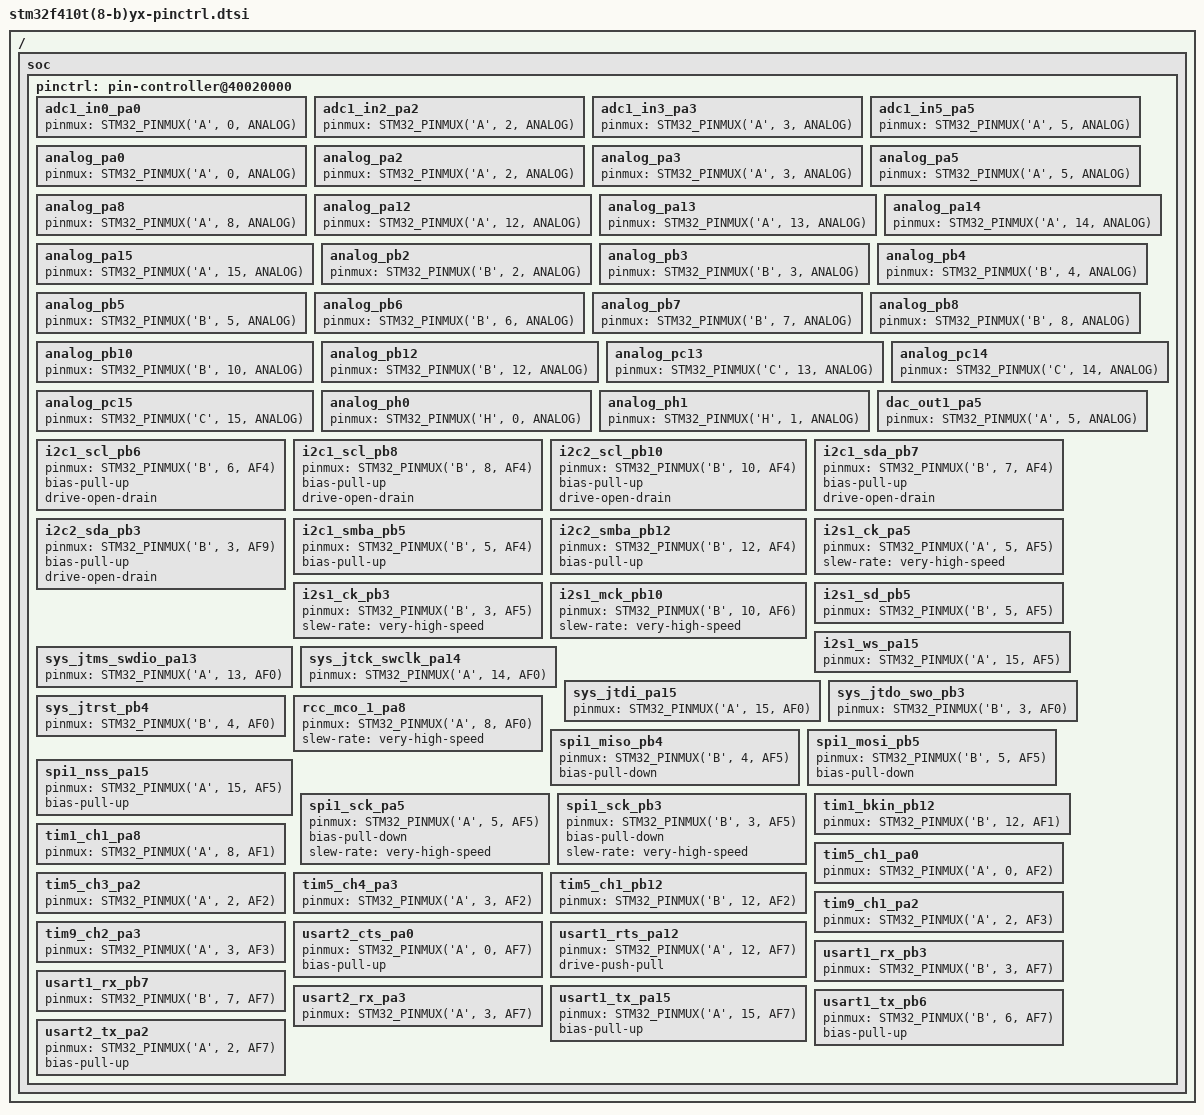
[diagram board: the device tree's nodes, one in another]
/*
 * NOTE: Autogenerated file using genpinctrl.py
 *
 * SPDX-License-Identifier: Apache-2.0
 */

#include <zephyr/dt-bindings/pinctrl/stm32-pinctrl.h>

/ {
	soc {
		pinctrl: pin-controller@40020000 {

			/* ADC_IN / ADC_INN / ADC_INP */

			/omit-if-no-ref/ adc1_in0_pa0: adc1_in0_pa0 {
				pinmux = <STM32_PINMUX('A', 0, ANALOG)>;
			};

			/omit-if-no-ref/ adc1_in2_pa2: adc1_in2_pa2 {
				pinmux = <STM32_PINMUX('A', 2, ANALOG)>;
			};

			/omit-if-no-ref/ adc1_in3_pa3: adc1_in3_pa3 {
				pinmux = <STM32_PINMUX('A', 3, ANALOG)>;
			};

			/omit-if-no-ref/ adc1_in5_pa5: adc1_in5_pa5 {
				pinmux = <STM32_PINMUX('A', 5, ANALOG)>;
			};

			/* Analog */

			/omit-if-no-ref/ analog_pa0: analog_pa0 {
				pinmux = <STM32_PINMUX('A', 0, ANALOG)>;
			};

			/omit-if-no-ref/ analog_pa2: analog_pa2 {
				pinmux = <STM32_PINMUX('A', 2, ANALOG)>;
			};

			/omit-if-no-ref/ analog_pa3: analog_pa3 {
				pinmux = <STM32_PINMUX('A', 3, ANALOG)>;
			};

			/omit-if-no-ref/ analog_pa5: analog_pa5 {
				pinmux = <STM32_PINMUX('A', 5, ANALOG)>;
			};

			/omit-if-no-ref/ analog_pa8: analog_pa8 {
				pinmux = <STM32_PINMUX('A', 8, ANALOG)>;
			};

			/omit-if-no-ref/ analog_pa12: analog_pa12 {
				pinmux = <STM32_PINMUX('A', 12, ANALOG)>;
			};

			/omit-if-no-ref/ analog_pa13: analog_pa13 {
				pinmux = <STM32_PINMUX('A', 13, ANALOG)>;
			};

			/omit-if-no-ref/ analog_pa14: analog_pa14 {
				pinmux = <STM32_PINMUX('A', 14, ANALOG)>;
			};

			/omit-if-no-ref/ analog_pa15: analog_pa15 {
				pinmux = <STM32_PINMUX('A', 15, ANALOG)>;
			};

			/omit-if-no-ref/ analog_pb2: analog_pb2 {
				pinmux = <STM32_PINMUX('B', 2, ANALOG)>;
			};

			/omit-if-no-ref/ analog_pb3: analog_pb3 {
				pinmux = <STM32_PINMUX('B', 3, ANALOG)>;
			};

			/omit-if-no-ref/ analog_pb4: analog_pb4 {
				pinmux = <STM32_PINMUX('B', 4, ANALOG)>;
			};

			/omit-if-no-ref/ analog_pb5: analog_pb5 {
				pinmux = <STM32_PINMUX('B', 5, ANALOG)>;
			};

			/omit-if-no-ref/ analog_pb6: analog_pb6 {
				pinmux = <STM32_PINMUX('B', 6, ANALOG)>;
			};

			/omit-if-no-ref/ analog_pb7: analog_pb7 {
				pinmux = <STM32_PINMUX('B', 7, ANALOG)>;
			};

			/omit-if-no-ref/ analog_pb8: analog_pb8 {
				pinmux = <STM32_PINMUX('B', 8, ANALOG)>;
			};

			/omit-if-no-ref/ analog_pb10: analog_pb10 {
				pinmux = <STM32_PINMUX('B', 10, ANALOG)>;
			};

			/omit-if-no-ref/ analog_pb12: analog_pb12 {
				pinmux = <STM32_PINMUX('B', 12, ANALOG)>;
			};

			/omit-if-no-ref/ analog_pc13: analog_pc13 {
				pinmux = <STM32_PINMUX('C', 13, ANALOG)>;
			};

			/omit-if-no-ref/ analog_pc14: analog_pc14 {
				pinmux = <STM32_PINMUX('C', 14, ANALOG)>;
			};

			/omit-if-no-ref/ analog_pc15: analog_pc15 {
				pinmux = <STM32_PINMUX('C', 15, ANALOG)>;
			};

			/omit-if-no-ref/ analog_ph0: analog_ph0 {
				pinmux = <STM32_PINMUX('H', 0, ANALOG)>;
			};

			/omit-if-no-ref/ analog_ph1: analog_ph1 {
				pinmux = <STM32_PINMUX('H', 1, ANALOG)>;
			};

			/* DAC_OUT */

			/omit-if-no-ref/ dac_out1_pa5: dac_out1_pa5 {
				pinmux = <STM32_PINMUX('A', 5, ANALOG)>;
			};

			/* I2C_SCL */

			/omit-if-no-ref/ i2c1_scl_pb6: i2c1_scl_pb6 {
				pinmux = <STM32_PINMUX('B', 6, AF4)>;
				bias-pull-up;
				drive-open-drain;
			};

			/omit-if-no-ref/ i2c1_scl_pb8: i2c1_scl_pb8 {
				pinmux = <STM32_PINMUX('B', 8, AF4)>;
				bias-pull-up;
				drive-open-drain;
			};

			/omit-if-no-ref/ i2c2_scl_pb10: i2c2_scl_pb10 {
				pinmux = <STM32_PINMUX('B', 10, AF4)>;
				bias-pull-up;
				drive-open-drain;
			};

			/* I2C_SDA */

			/omit-if-no-ref/ i2c1_sda_pb7: i2c1_sda_pb7 {
				pinmux = <STM32_PINMUX('B', 7, AF4)>;
				bias-pull-up;
				drive-open-drain;
			};

			/omit-if-no-ref/ i2c2_sda_pb3: i2c2_sda_pb3 {
				pinmux = <STM32_PINMUX('B', 3, AF9)>;
				bias-pull-up;
				drive-open-drain;
			};

			/* I2C_SMBA */

			/omit-if-no-ref/ i2c1_smba_pb5: i2c1_smba_pb5 {
				pinmux = <STM32_PINMUX('B', 5, AF4)>;
				bias-pull-up;
			};

			/omit-if-no-ref/ i2c2_smba_pb12: i2c2_smba_pb12 {
				pinmux = <STM32_PINMUX('B', 12, AF4)>;
				bias-pull-up;
			};

			/* I2S_CK */

			/omit-if-no-ref/ i2s1_ck_pa5: i2s1_ck_pa5 {
				pinmux = <STM32_PINMUX('A', 5, AF5)>;
				slew-rate = "very-high-speed";
			};

			/omit-if-no-ref/ i2s1_ck_pb3: i2s1_ck_pb3 {
				pinmux = <STM32_PINMUX('B', 3, AF5)>;
				slew-rate = "very-high-speed";
			};

			/* I2S_MCK */

			/omit-if-no-ref/ i2s1_mck_pb10: i2s1_mck_pb10 {
				pinmux = <STM32_PINMUX('B', 10, AF6)>;
				slew-rate = "very-high-speed";
			};

			/* I2S_SD */

			/omit-if-no-ref/ i2s1_sd_pb5: i2s1_sd_pb5 {
				pinmux = <STM32_PINMUX('B', 5, AF5)>;
			};

			/* I2S_WS */

			/omit-if-no-ref/ i2s1_ws_pa15: i2s1_ws_pa15 {
				pinmux = <STM32_PINMUX('A', 15, AF5)>;
			};

			/* JTAG PORT */

			/omit-if-no-ref/ sys_jtms_swdio_pa13: sys_jtms_swdio_pa13 {
				pinmux = <STM32_PINMUX('A', 13, AF0)>;
			};

			/omit-if-no-ref/ sys_jtck_swclk_pa14: sys_jtck_swclk_pa14 {
				pinmux = <STM32_PINMUX('A', 14, AF0)>;
			};

			/omit-if-no-ref/ sys_jtdi_pa15: sys_jtdi_pa15 {
				pinmux = <STM32_PINMUX('A', 15, AF0)>;
			};

			/omit-if-no-ref/ sys_jtdo_swo_pb3: sys_jtdo_swo_pb3 {
				pinmux = <STM32_PINMUX('B', 3, AF0)>;
			};

			/omit-if-no-ref/ sys_jtrst_pb4: sys_jtrst_pb4 {
				pinmux = <STM32_PINMUX('B', 4, AF0)>;
			};

			/* RCC_MCO */

			/omit-if-no-ref/ rcc_mco_1_pa8: rcc_mco_1_pa8 {
				pinmux = <STM32_PINMUX('A', 8, AF0)>;
				slew-rate = "very-high-speed";
			};

			/* SPI_MISO */

			/omit-if-no-ref/ spi1_miso_pb4: spi1_miso_pb4 {
				pinmux = <STM32_PINMUX('B', 4, AF5)>;
				bias-pull-down;
			};

			/* SPI_MOSI */

			/omit-if-no-ref/ spi1_mosi_pb5: spi1_mosi_pb5 {
				pinmux = <STM32_PINMUX('B', 5, AF5)>;
				bias-pull-down;
			};

			/* SPI_NSS */

			/omit-if-no-ref/ spi1_nss_pa15: spi1_nss_pa15 {
				pinmux = <STM32_PINMUX('A', 15, AF5)>;
				bias-pull-up;
			};

			/* SPI_SCK */

			/omit-if-no-ref/ spi1_sck_pa5: spi1_sck_pa5 {
				pinmux = <STM32_PINMUX('A', 5, AF5)>;
				bias-pull-down;
				slew-rate = "very-high-speed";
			};

			/omit-if-no-ref/ spi1_sck_pb3: spi1_sck_pb3 {
				pinmux = <STM32_PINMUX('B', 3, AF5)>;
				bias-pull-down;
				slew-rate = "very-high-speed";
			};

			/* TIM_BKIN */

			/omit-if-no-ref/ tim1_bkin_pb12: tim1_bkin_pb12 {
				pinmux = <STM32_PINMUX('B', 12, AF1)>;
			};

			/* TIM_CH / TIM_CHN */

			/omit-if-no-ref/ tim1_ch1_pa8: tim1_ch1_pa8 {
				pinmux = <STM32_PINMUX('A', 8, AF1)>;
			};

			/omit-if-no-ref/ tim5_ch1_pa0: tim5_ch1_pa0 {
				pinmux = <STM32_PINMUX('A', 0, AF2)>;
			};

			/omit-if-no-ref/ tim5_ch3_pa2: tim5_ch3_pa2 {
				pinmux = <STM32_PINMUX('A', 2, AF2)>;
			};

			/omit-if-no-ref/ tim5_ch4_pa3: tim5_ch4_pa3 {
				pinmux = <STM32_PINMUX('A', 3, AF2)>;
			};

			/omit-if-no-ref/ tim5_ch1_pb12: tim5_ch1_pb12 {
				pinmux = <STM32_PINMUX('B', 12, AF2)>;
			};

			/omit-if-no-ref/ tim9_ch1_pa2: tim9_ch1_pa2 {
				pinmux = <STM32_PINMUX('A', 2, AF3)>;
			};

			/omit-if-no-ref/ tim9_ch2_pa3: tim9_ch2_pa3 {
				pinmux = <STM32_PINMUX('A', 3, AF3)>;
			};

			/* UART_CTS / USART_CTS / LPUART_CTS */

			/omit-if-no-ref/ usart2_cts_pa0: usart2_cts_pa0 {
				pinmux = <STM32_PINMUX('A', 0, AF7)>;
				bias-pull-up;
			};

			/* UART_RTS / USART_RTS / LPUART_RTS */

			/omit-if-no-ref/ usart1_rts_pa12: usart1_rts_pa12 {
				pinmux = <STM32_PINMUX('A', 12, AF7)>;
				drive-push-pull;
			};

			/* UART_RX / USART_RX / LPUART_RX */

			/omit-if-no-ref/ usart1_rx_pb3: usart1_rx_pb3 {
				pinmux = <STM32_PINMUX('B', 3, AF7)>;
			};

			/omit-if-no-ref/ usart1_rx_pb7: usart1_rx_pb7 {
				pinmux = <STM32_PINMUX('B', 7, AF7)>;
			};

			/omit-if-no-ref/ usart2_rx_pa3: usart2_rx_pa3 {
				pinmux = <STM32_PINMUX('A', 3, AF7)>;
			};

			/* UART_TX / USART_TX / LPUART_TX */

			/omit-if-no-ref/ usart1_tx_pa15: usart1_tx_pa15 {
				pinmux = <STM32_PINMUX('A', 15, AF7)>;
				bias-pull-up;
			};

			/omit-if-no-ref/ usart1_tx_pb6: usart1_tx_pb6 {
				pinmux = <STM32_PINMUX('B', 6, AF7)>;
				bias-pull-up;
			};

			/omit-if-no-ref/ usart2_tx_pa2: usart2_tx_pa2 {
				pinmux = <STM32_PINMUX('A', 2, AF7)>;
				bias-pull-up;
			};

		};
	};
};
